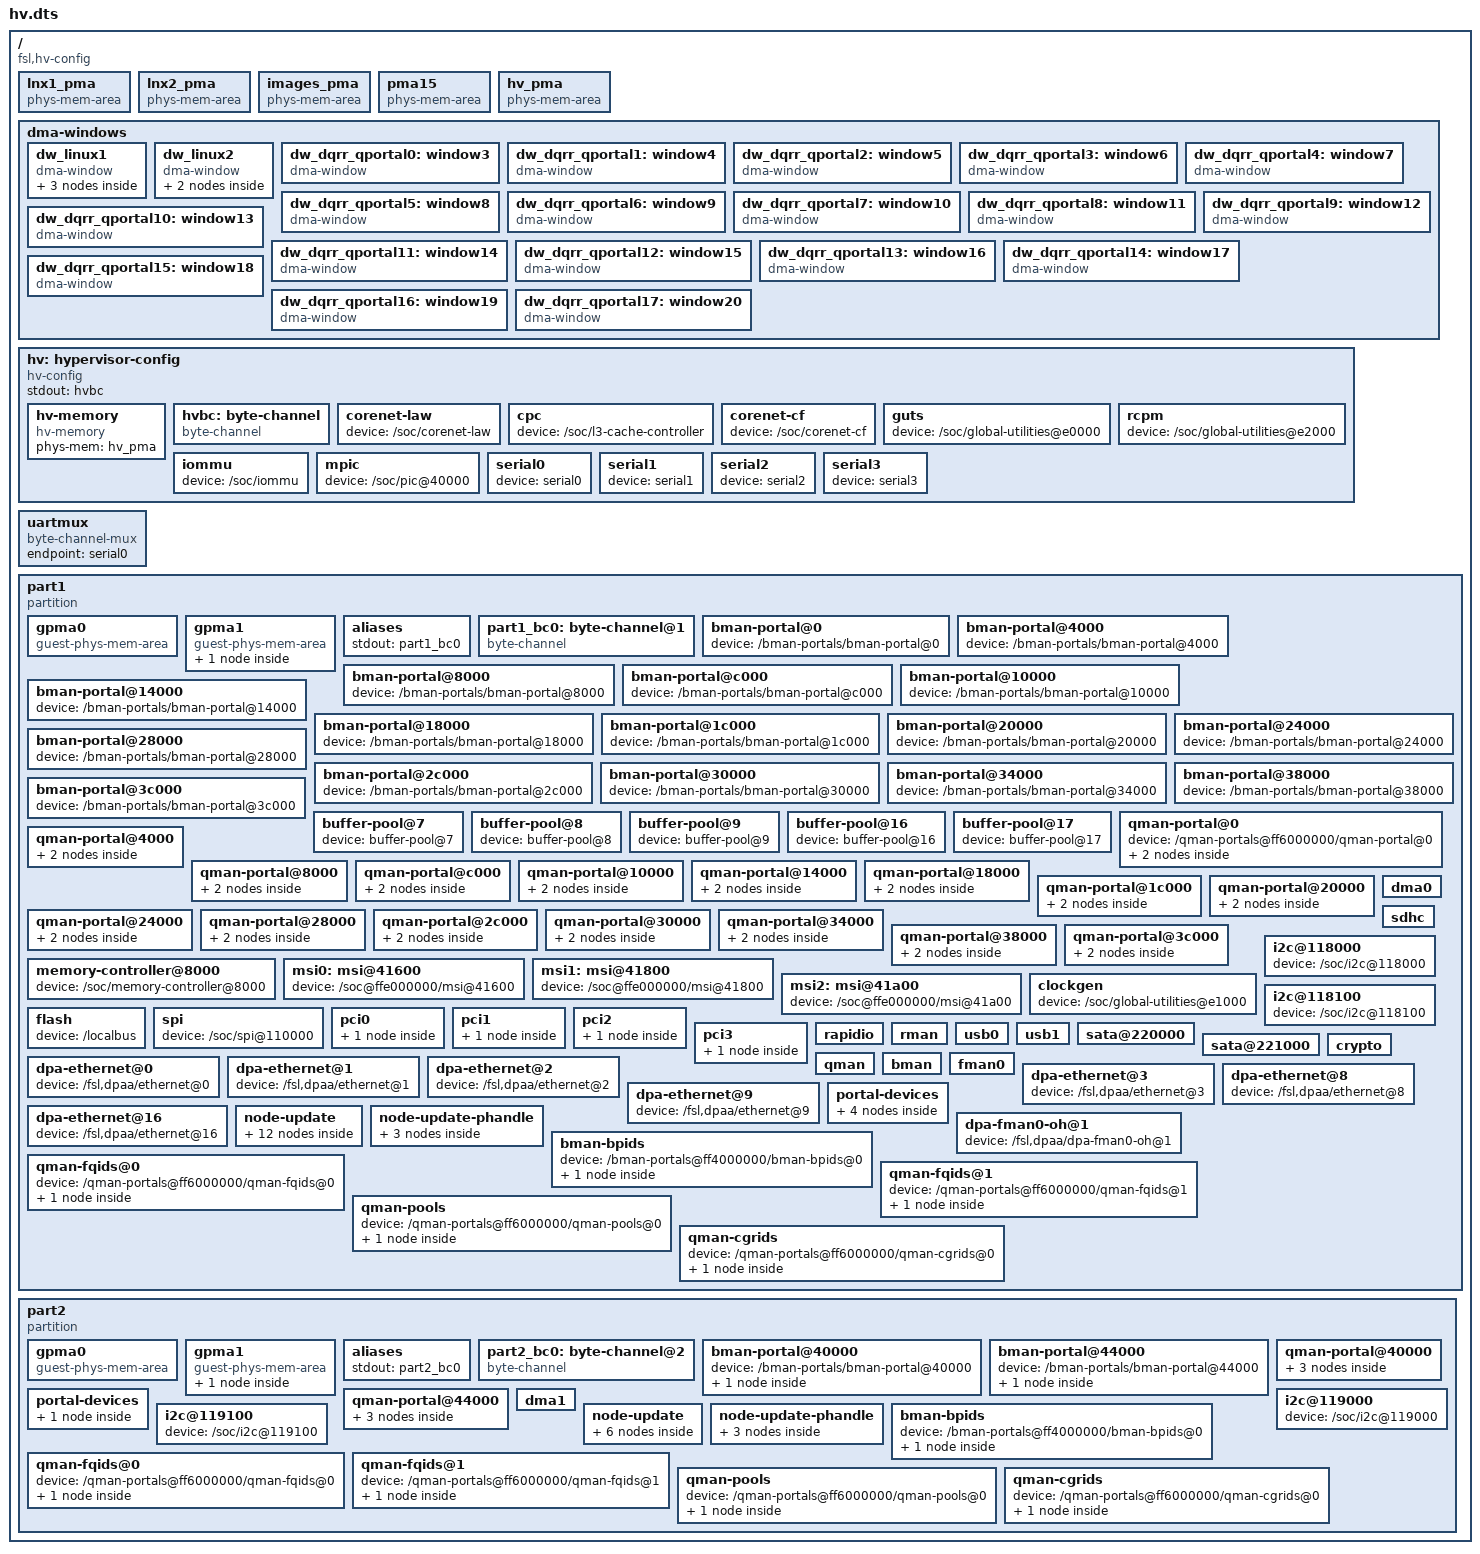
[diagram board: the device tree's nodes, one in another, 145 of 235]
/* Hypervisor Configuration tree containing all hypervisor configuration
 * parameters and partition definition information.
 * (Note -- Please refer to Hypervisor SW Reference Manual
 * (Chapter 5 Configuration) for further details)
 *
 * Copyright 2013 Freescale Semiconductor, Inc.
 */

/dts-v1/;

/ {	// root node

	// The root node of the configuration device tree must contain a
	// compatible property that identifies the device tree as a hypervisor

	compatible = "fsl,hv-config";

	// =====================================================
	// Physical Memory Areas
	// =====================================================
	lnx1_pma: lnx1_pma {
		compatible = "phys-mem-area";
		addr = <0x0 0x00000000>;	// Linux
		size = <0x0 0x40000000>;	// 1GB
	};

	lnx2_pma: lnx2_pma {
		compatible = "phys-mem-area";
		addr = <0x0 0x40000000>;	// Linux
		size = <0x0 0x20000000>;	// 512MB
	};

	images_pma: images_pma {
		compatible = "phys-mem-area";
		addr = <0x0 0x78000000>;	// Used for boot-from-RAM
		size = <0x0 0x04000000>;	// 64MB
	};

	pma15: pma15 {
		compatible = "phys-mem-area";
		addr = <0x0 0x7c000000>;	// For MAC-less Ethernet Linux1 and Linux2
		size = <0x0 0x01000000>;	// 16MB
	};

	hv_pma: hv_pma {
		compatible = "phys-mem-area";
		addr = <0x0 0x7f000000>;	// Hypervisor
		size = <0x0 0x01000000>;	// 16MB
	};

	// =====================================================
	// DMA Windows
	// =====================================================
	dma-windows {
		// DMA window for part1_linux
		dw_linux1: dw_linux1 {
			compatible = "dma-window";
			guest-addr = <0 0>;
			size = <0x1 0x00000000>; // 4GB
			subwindow-count = <4>;

			sub-window@0 {
				compatible = "dma-subwindow";
				guest-addr = <0 0>;
				size = <0 0x40000000>; // 1GB
			};

			// ====================================================
			// The window is used for MSIIR translation. The
			// hypervisor sets  a property in the guest device tree
			// (msi-address-64) which indicates the guest physical
			// address of the MSIIR register.
			// This address must be in the next page after the end
			// of DDR as seen by the guest. This is because, Linux
			// is extending the DDR ATMU with one page in order to
			// cover the MSIIR register.
			// ====================================================
			sub-window@1 {		// MSI sub-window
				compatible = "dma-subwindow";
				guest-addr = <0 0x40000000>;
				size = <0 0x1000>; // 4KB
				pcie-msi-subwindow;
			};

			sub-window@2 {		// Inter-partition region
				compatible = "dma-subwindow";
				guest-addr = <0 0x80000000>;
				size = <0 0x1000000>; // 16MB
			};
		};

		// DMA window for part2_linux
		dw_linux2: dw_linux2 {
			compatible = "dma-window";
			guest-addr = <0 0>;
			size = <0x1 0x00000000>; // 4GB
			subwindow-count = <4>;

			sub-window@0 {
				compatible = "dma-subwindow";
				guest-addr = <0 0>;
				size = <0 0x20000000>; // 512MB
			};

			sub-window@1 {		// Inter-partition region
				compatible = "dma-subwindow";
				guest-addr = <0 0x80000000>;
				size = <0 0x1000000>; // 16MB
			};
		};

		// DMA window for stash_dqrr for qman-portal0
		dw_dqrr_qportal0: window3 {
			compatible = "dma-window";
			guest-addr = <0xf 0xf6000000>;
			size = <0 0x4000>;
		};

		// DMA window for stash_dqrr for qman-portal1
		dw_dqrr_qportal1: window4 {
			compatible = "dma-window";
			guest-addr = <0xf 0xf6004000>;
			size = <0 0x4000>;
		};

		// DMA window for stash_dqrr for qman-portal2
		dw_dqrr_qportal2: window5 {
			compatible = "dma-window";
			guest-addr = <0xf 0xf6008000>;
			size = <0 0x4000>;
		};

		// DMA window for stash_dqrr for qman-portal3
		dw_dqrr_qportal3: window6 {
			compatible = "dma-window";
			guest-addr = <0xf 0xf600c000>;
			size = <0 0x4000>;
		};

		// DMA window for stash_dqrr for qman-portal4
		dw_dqrr_qportal4: window7 {
			compatible = "dma-window";
			guest-addr = <0xf 0xf6010000>;
			size = <0 0x4000>;
		};

		// DMA window for stash_dqrr for qman-portal5
		dw_dqrr_qportal5: window8 {
			compatible = "dma-window";
			guest-addr = <0xf 0xf6014000>;
			size = <0 0x4000>;
		};

		// DMA window for stash_dqrr for qman-portal6
		dw_dqrr_qportal6: window9 {
			compatible = "dma-window";
			guest-addr = <0xf 0xf6018000>;
			size = <0 0x4000>;
		};

		// DMA window for stash_dqrr for qman-portal7
		dw_dqrr_qportal7: window10 {
			compatible = "dma-window";
			guest-addr = <0xf 0xf601c000>;
			size = <0 0x4000>;
		};

		// DMA window for stash_dqrr for qman-portal8
		dw_dqrr_qportal8: window11 {
			compatible = "dma-window";
			guest-addr = <0xf 0xf6020000>;
			size = <0 0x4000>;
		};

		// DMA window for stash_dqrr for qman-portal9
		dw_dqrr_qportal9: window12 {
			compatible = "dma-window";
			guest-addr = <0xf 0xf6024000>;
			size = <0 0x4000>;
		};

		// DMA window for stash_dqrr for qman-portal10
		dw_dqrr_qportal10: window13 {
			compatible = "dma-window";
			guest-addr = <0xf 0xf6028000>;
			size = <0 0x4000>;
		};

		// DMA window for stash_dqrr for qman-portal11
		dw_dqrr_qportal11: window14 {
			compatible = "dma-window";
			guest-addr = <0xf 0xf602c000>;
			size = <0 0x4000>;
		};

		// DMA window for stash_dqrr for qman-portal12
		dw_dqrr_qportal12: window15 {
			compatible = "dma-window";
			guest-addr = <0xf 0xf6030000>;
			size = <0 0x4000>;
		};

		// DMA window for stash_dqrr for qman-portal13
		dw_dqrr_qportal13: window16 {
			compatible = "dma-window";
			guest-addr = <0xf 0xf6034000>;
			size = <0 0x4000>;
		};

		// DMA window for stash_dqrr for qman-portal14
		dw_dqrr_qportal14: window17 {
			compatible = "dma-window";
			guest-addr = <0xf 0xf6038000>;
			size = <0 0x4000>;
		};

		// DMA window for stash_dqrr for qman-portal15
		dw_dqrr_qportal15: window18 {
			compatible = "dma-window";
			guest-addr = <0xf 0xf603c000>;
			size = <0 0x4000>;
		};

		// DMA window for stash_dqrr for qman-portal16
		dw_dqrr_qportal16: window19 {
			compatible = "dma-window";
			guest-addr = <0xf 0xf6040000>;
			size = <0 0x4000>;
		};

		// DMA window for stash_dqrr for qman-portal17
		dw_dqrr_qportal17: window20 {
			compatible = "dma-window";
			guest-addr = <0xf 0xf6044000>;
			size = <0 0x4000>;
		};
	};

	// =====================================================
	// Hypervisor Config
	// Hypervisor is also configured via the Hypervisor
	// configuration tree. A special node and subtree defines
	// set of global configuration parameters and a number of
	// device nodes assigning I/O devices to the hypervisor
	// =====================================================
	hv: hypervisor-config {
		compatible = "hv-config";

		// phandle to byte-channel used for hypervisor's console
		stdout = <&hvbc>;

		hv-memory {
			compatible = "hv-memory";
			phys-mem = <&hv_pma>;
		};

		hvbc: byte-channel {
			compatible = "byte-channel";
			endpoint = <&uartmux>;
			mux-channel = <0>;
		};

		// Device nodes given below are the physical I/O
		// devices assigned to hypervisor
		corenet-law {
			device = "/soc/corenet-law";
		};

		cpc {
			device = "/soc/l3-cache-controller";
		};

		corenet-cf {
			device = "/soc/corenet-cf";
		};

		guts {
			device = "/soc/global-utilities@e0000";
		};

		rcpm {
			device = "/soc/global-utilities@e2000";
		};

		iommu {
			device = "/soc/iommu";
		};

		mpic {
			device = "/soc/pic@40000";
		};

		serial0: serial0 {
			device = "serial0";
		};

		serial1: serial1 {
			device = "serial1";
		};

		serial2: serial2 {
			device = "serial2";
		};

		serial3: serial3 {
			device = "serial3";
		};
	};

	// =====================================================
	// UART mux
	// This node is referenced by byte-channels that use mux
	// as an endpoint
	// =====================================================
	uartmux: uartmux {
		compatible = "byte-channel-mux";
		endpoint = <&serial0>;
	};

	// =====================================================
	// To keep the scenarios hv-1/2/4p as diff-able as possible
	// we always use labels part1, part2, part<n>
	// In hv-2p scenario, there are 2 partitions - 2 Linux
	// Partition1 --- part1 --- Linux partition
	// Partition2 --- part2 --- Linux partition
	// =====================================================

	// =====================================================
	// Partition 1
	// =====================================================
	part1 {
		// Indicates that it is a partition node
		compatible = "partition";
		label = "p1-linux";
		// CPUs #0 to #6 are assigned to this partition
		cpus = <0 7>;
		guest-image = <0xf 0xe8020000 0 0 0 0x700000>;
		linux-rootfs = <0xf 0xe9300000 0 0x01300000 0 0x02800000>;
		dtb-window = <0 0x1000000 0 0x20000>;

		// Temporary until Linux uses enable LIODN hcall
		no-dma-disable;
		direct-guest-tlb-miss;
		direct-guest-tlb-management;

		gpma0 {
			compatible = "guest-phys-mem-area";
			phys-mem = <&lnx1_pma>;
			guest-addr = <0 0>;
		};

		gpma1 {
			compatible = "guest-phys-mem-area";
			phys-mem = <&pma15>;	// Interpartition between Linux1 - Linux2
			guest-addr = <0 0x80000000>;
			node-update {
				delete-prop = "device_type";
			};
		};

		aliases {
			stdout = <&part1_bc0>;
		};

		// =====================================================
		// Devices assigned to the partition - device nodes
		// device node is child of partition node and is used to
		// assign physical I/O devices to partition
		// =====================================================
		part1_bc0: byte-channel@1 {
			compatible = "byte-channel";
			endpoint = <&uartmux>;
			mux-channel = <1>;
		};

		// Bman portals assigned to this partition
		bman-portal@0 {
			device = "/bman-portals/bman-portal@0";
		};

		bman-portal@4000 {
			device = "/bman-portals/bman-portal@4000";
		};

		bman-portal@8000 {
			device = "/bman-portals/bman-portal@8000";
		};

		bman-portal@c000 {
			device = "/bman-portals/bman-portal@c000";
		};

		bman-portal@10000 {
			device = "/bman-portals/bman-portal@10000";
		};

		bman-portal@14000 {
			device = "/bman-portals/bman-portal@14000";
		};

		bman-portal@18000 {
			device = "/bman-portals/bman-portal@18000";
		};

		bman-portal@1c000 {
			device = "/bman-portals/bman-portal@1c000";
		};

		bman-portal@20000 {
			device = "/bman-portals/bman-portal@20000";
		};

		bman-portal@24000 {
			device = "/bman-portals/bman-portal@24000";
		};

		bman-portal@28000 {
			device = "/bman-portals/bman-portal@28000";
		};

		bman-portal@2c000 {
			device = "/bman-portals/bman-portal@2c000";
		};

		bman-portal@30000 {
			device = "/bman-portals/bman-portal@30000";
		};

		bman-portal@34000 {
			device = "/bman-portals/bman-portal@34000";
		};

		bman-portal@38000 {
			device = "/bman-portals/bman-portal@38000";
		};

		bman-portal@3c000 {
			device = "/bman-portals/bman-portal@3c000";
		};

		// Bman buffer pools assigned to this partition
		buffer-pool@7 {
			device = "buffer-pool@7";
		};

		buffer-pool@8 {
			device = "buffer-pool@8";
		};

		buffer-pool@9 {
			device = "buffer-pool@9";
		};

		buffer-pool@16 {
			device = "buffer-pool@16";
		};

		buffer-pool@17 {
			device = "buffer-pool@17";
		};

		qman-portal@0 {
			device = "/qman-portals@ff6000000/qman-portal@0";

			stash-mem {
				liodn-index = <1>;
				dma-window = <&dw_linux1>;
				operation-mapping = <0>;
				stash-dest = <3>;
			};

			stash-dqrr {
				liodn-index = <0>;
				dma-window = <&dw_dqrr_qportal0>;
				operation-mapping = <0>;
				stash-dest = <3>;
			};
		};

		qman-portal@4000 {
			device = "/qman-portals@ff6000000/qman-portal@4000";

			stash-mem {
				liodn-index = <1>;
				dma-window = <&dw_linux1>;
				operation-mapping = <0>;
				stash-dest = <3>;
			};

			stash-dqrr {
				liodn-index = <0>;
				dma-window = <&dw_dqrr_qportal1>;
				operation-mapping = <0>;
				stash-dest = <3>;
			};
		};

		qman-portal@8000 {
			device = "/qman-portals@ff6000000/qman-portal@8000";

			stash-mem {
				liodn-index = <1>;
				dma-window = <&dw_linux1>;
				operation-mapping = <0>;
				stash-dest = <3>;
			};

			stash-dqrr {
				liodn-index = <0>;
				dma-window = <&dw_dqrr_qportal2>;
				operation-mapping = <0>;
				stash-dest = <3>;
			};
		};

		qman-portal@c000 {
			device = "/qman-portals@ff6000000/qman-portal@c000";

			stash-mem {
				liodn-index = <1>;
				dma-window = <&dw_linux1>;
				operation-mapping = <0>;
				stash-dest = <3>;
			};

			stash-dqrr {
				liodn-index = <0>;
				dma-window = <&dw_dqrr_qportal3>;
				operation-mapping = <0>;
				stash-dest = <3>;
			};
		};

		qman-portal@10000 {
			device = "/qman-portals@ff6000000/qman-portal@10000";

			stash-mem {
				liodn-index = <1>;
				dma-window = <&dw_linux1>;
				operation-mapping = <0>;
				stash-dest = <3>;
			};

			stash-dqrr {
				liodn-index = <0>;
				dma-window = <&dw_dqrr_qportal4>;
				operation-mapping = <0>;
				stash-dest = <3>;
			};
		};

		qman-portal@14000 {
			device = "/qman-portals@ff6000000/qman-portal@14000";

			stash-mem {
				liodn-index = <1>;
				dma-window = <&dw_linux1>;
				operation-mapping = <0>;
				stash-dest = <3>;
			};

			stash-dqrr {
				liodn-index = <0>;
				dma-window = <&dw_dqrr_qportal5>;
				operation-mapping = <0>;
				stash-dest = <3>;
			};
		};

		qman-portal@18000 {
			device = "/qman-portals@ff6000000/qman-portal@18000";

			stash-mem {
				liodn-index = <1>;
				dma-window = <&dw_linux1>;
				operation-mapping = <0>;
				stash-dest = <3>;
			};

			stash-dqrr {
				liodn-index = <0>;
				dma-window = <&dw_dqrr_qportal6>;
				operation-mapping = <0>;
				stash-dest = <3>;
			};
		};

		qman-portal@1c000 {
			device = "/qman-portals@ff6000000/qman-portal@1c000";

			stash-mem {
				liodn-index = <1>;
				dma-window = <&dw_linux1>;
				operation-mapping = <0>;
				stash-dest = <3>;
			};

			stash-dqrr {
				liodn-index = <0>;
				dma-window = <&dw_dqrr_qportal7>;
				operation-mapping = <0>;
				stash-dest = <3>;
			};
		};

		qman-portal@20000 {
			device = "/qman-portals@ff6000000/qman-portal@20000";

			stash-mem {
				liodn-index = <1>;
				dma-window = <&dw_linux1>;
				operation-mapping = <0>;
				stash-dest = <3>;
			};

			stash-dqrr {
				liodn-index = <0>;
				dma-window = <&dw_dqrr_qportal8>;
				operation-mapping = <0>;
				stash-dest = <3>;
			};
		};

		qman-portal@24000 {
			device = "/qman-portals@ff6000000/qman-portal@24000";

			stash-mem {
				liodn-index = <1>;
				dma-window = <&dw_linux1>;
				operation-mapping = <0>;
				stash-dest = <3>;
			};

			stash-dqrr {
				liodn-index = <0>;
				dma-window = <&dw_dqrr_qportal9>;
				operation-mapping = <0>;
				stash-dest = <3>;
			};
		};

		qman-portal@28000 {
			device = "/qman-portals@ff6000000/qman-portal@28000";

			stash-mem {
				liodn-index = <1>;
				dma-window = <&dw_linux1>;
				operation-mapping = <0>;
				stash-dest = <3>;
			};

			stash-dqrr {
				liodn-index = <0>;
				dma-window = <&dw_dqrr_qportal10>;
				operation-mapping = <0>;
				stash-dest = <3>;
			};
		};

		qman-portal@2c000 {
			device = "/qman-portals@ff6000000/qman-portal@2c000";

			stash-mem {
				liodn-index = <1>;
				dma-window = <&dw_linux1>;
				operation-mapping = <0>;
				stash-dest = <3>;
			};

			stash-dqrr {
				liodn-index = <0>;
				dma-window = <&dw_dqrr_qportal11>;
				operation-mapping = <0>;
				stash-dest = <3>;
			};
		};

		qman-portal@30000 {
			device = "/qman-portals@ff6000000/qman-portal@30000";

			stash-mem {
				liodn-index = <1>;
				dma-window = <&dw_linux1>;
				operation-mapping = <0>;
				stash-dest = <3>;
			};

			stash-dqrr {
				liodn-index = <0>;
				dma-window = <&dw_dqrr_qportal12>;
				operation-mapping = <0>;
				stash-dest = <3>;
			};
		};

		qman-portal@34000 {
			device = "/qman-portals@ff6000000/qman-portal@34000";

			stash-mem {
				liodn-index = <1>;
				dma-window = <&dw_linux1>;
				operation-mapping = <0>;
				stash-dest = <3>;
			};

			stash-dqrr {
				liodn-index = <0>;
				dma-window = <&dw_dqrr_qportal13>;
				operation-mapping = <0>;
				stash-dest = <3>;
			};
		};

		qman-portal@38000 {
			device = "/qman-portals@ff6000000/qman-portal@38000";

			stash-mem {
				liodn-index = <1>;
				dma-window = <&dw_linux1>;
				operation-mapping = <0>;
				stash-dest = <3>;
			};

			stash-dqrr {
				liodn-index = <0>;
				dma-window = <&dw_dqrr_qportal14>;
				operation-mapping = <0>;
				stash-dest = <3>;
			};
		};

		qman-portal@3c000 {
			device = "/qman-portals@ff6000000/qman-portal@3c000";

			stash-mem {
				liodn-index = <1>;
				dma-window = <&dw_linux1>;
				operation-mapping = <0>;
				stash-dest = <3>;
			};

			stash-dqrr {
				liodn-index = <0>;
				dma-window = <&dw_dqrr_qportal15>;
				operation-mapping = <0>;
				stash-dest = <3>;
			};
		};

		memory-controller@8000 {
			device = "/soc/memory-controller@8000";
		};

		msi0: msi@41600 {
			device = "/soc@ffe000000/msi@41600";
		};

		msi1: msi@41800 {
			device = "/soc@ffe000000/msi@41800";
		};

		msi2: msi@41a00 {
			device = "/soc@ffe000000/msi@41a00";
		};

		dma0 {
			device = "dma0";
			dma-window = <&dw_linux1>;
		};

		sdhc {
			device = "sdhc";
			dma-window = <&dw_linux1>;
		};

		clockgen {
			device = "/soc/global-utilities@e1000";
		};

		i2c@118000 {
			device = "/soc/i2c@118000";
		};

		i2c@118100 {
			device = "/soc/i2c@118100";
		};

		flash {
			device = "/localbus";
		};

		spi {
			device = "/soc/spi@110000";
		};

		pci0 {
			device = "pci0";
			map-ranges;
			dma-window = <&dw_linux1>;
			node-update-phandle {
				fsl,msi = <&msi0>;
			};
		};

		pci1 {
			device = "pci1";
			map-ranges;
			dma-window = <&dw_linux1>;
			node-update-phandle {
				fsl,msi = <&msi1>;
			};
		};

		pci2 {
			device = "pci2";
			map-ranges;
			dma-window = <&dw_linux1>;
			node-update-phandle {
				fsl,msi = <&msi2>;
			};
		};

		pci3 {
			device = "pci3";
			map-ranges;
			dma-window = <&dw_linux1>;
			node-update-phandle {
				fsl,msi = <&msi0>;
			};
		};

		rapidio {
			device = "rapidio@ffe0c0000";
			map-ranges;
			dma-window = <&dw_linux1>;
		};

		rman {
			device = "rman";
			dma-window = <&dw_linux1>;
		};

		usb0 {
			device = "/soc/usb@210000";
			dma-window = <&dw_linux1>;
		};

		usb1 {
			device = "usb1";
			dma-window = <&dw_linux1>;
		};

		sata@220000 {
			device = "/soc/sata@220000";
			dma-window = <&dw_linux1>;
		};

		sata@221000 {
			device = "/soc/sata@221000";
			dma-window = <&dw_linux1>;
		};

		crypto {
			device = "/soc/crypto";
			dma-window = <&dw_linux1>;
		};

		qman {
			device = "/soc/qman";
			dma-window = <&dw_linux1>;
			operation-mapping = <2>;	// OMI_QMAN_PRIV
			stash-dest = <3>;		// L3/CPC
		};

		bman {
			device = "/soc/bman";
			dma-window = <&dw_linux1>;
		};

		fman0 {
			device = "fman0";
			dma-window = <&dw_linux1>;
		};

		// FMAN0 XAUI - ethernet 0 assigned to this partition
		dpa-ethernet@0 {
			device = "/fsl,dpaa/ethernet@0";
		};

		// FMAN0 XAUI - ethernet 1 assigned to this partition
		dpa-ethernet@1 {
			device = "/fsl,dpaa/ethernet@1";
		};

		// FMAN0 RGMII -- ethernet 2 assigned to this partition
		dpa-ethernet@2 {
			device = "/fsl,dpaa/ethernet@2";
		};

		// FMAN0 RGMII -- ethernet 3 assigned to this partition
		dpa-ethernet@3 {
			device = "/fsl,dpaa/ethernet@3";
		};

		// FMAN0 XAUI - ethernet 8 assigned to this partition
		dpa-ethernet@8 {
			device = "/fsl,dpaa/ethernet@8";
		};

		// FMAN0 XAUI - ethernet 9 assigned to this partition
		dpa-ethernet@9 {
			device = "/fsl,dpaa/ethernet@9";
		};

		// MAC-less b/w kernel and USDPAA -- assigned to this partition
		dpa-ethernet@16 {
			device = "/fsl,dpaa/ethernet@16";
		};
		portal-devices {
			fman0 {
				device = "fman0";
				dma-window = <&dw_linux1>;
			};

			caam {
				device = "crypto";
				dma-window = <&dw_linux1>;
			};

			pme {
				device = "pme";
				dma-window = <&dw_linux1>;
			};

			rman {
				device = "rman";
				dma-window = <&dw_linux1>;
			};
		};

		node-update {
			#address-cells = <0x2>;
			#size-cells = <0x2>;
			reserved-memory {
				#address-cells = <0x2>;
				#size-cells = <0x2>;
				ranges;

				bman-fbpr {
					size = <0x0 0x1000000>;
					alignment = <0x0 0x1000000>;
					compatible = "fsl,bman-fbpr";
					alloc-ranges = <0x0 0x0 0x10000 0x0>;
					linux,phandle = <0x2a>;
					phandle = <0x2a>;
				};

				qman-fqd {
					size = <0x0 0x800000>;
					alignment = <0x0 0x800000>;
					compatible = "fsl,qman-fqd";
					alloc-ranges = <0x0 0x0 0x10000 0x0>;
					linux,phandle = <0x2c>;
					phandle = <0x2c>;
				};

				qman-pfdr {
					size = <0x0 0x2000000>;
					alignment = <0x0 0x2000000>;
					compatible = "fsl,qman-pfdr";
					alloc-ranges = <0x0 0x0 0x10000 0x0>;
					linux,phandle = <0x2d>;
					phandle = <0x2d>;
				};

				pme-pdsr {
					compatible = "fsl,pme-pdsr";
					alloc-ranges = <0x0 0x0 0x10000 0x0>;
					size = <0x0 0x1000000>;
					alignment = <0x0 0x1000000>;
					linux,phandle = <0x27>;
					phandle = <0x27>;
				};

				pme-sre {
					compatible = "fsl,pme-sre";
					alloc-ranges = <0x0 0x0 0x10000 0x0>;
					size = <0x0 0xa00000>;
					alignment = <0x0 0xa00000>;
					linux,phandle = <0x28>;
					phandle = <0x28>;
				};
			};

			// =====================================================
			// The buffer size value of 1728 (multiple of ODD cache
			// line) is calculated according to dpa_extra_headroom
			// which defaults to 64bytes.
			// If dpa_extra_headroom is set to 0 then the buffer
			// size will be 1600bytes (also multiple of odd cache
			// line). For any extra headroom values ranging between
			// 1 and 128bytes the buffer size is 1728bytes. For
			// values ranging between 129bytes and 256bytes, the
			// buffer size is 1856bytes and so on.
			// =====================================================
			part1_bp10: buffer-pool@10 {
				compatible = "fsl,t2080-bpool", "fsl,bpool";
				fsl,bpid = <10>;
				fsl,bpool-ethernet-cfg = <0 0x80 0 1728 0 0x80000000>;
				fsl,bpool-ethernet-seeds;
			};

			// =====================================================
			// Same comment as for part1_bp10
			// =====================================================
			part1_bp11: buffer-pool@11 {
				compatible = "fsl,t2080-bpool", "fsl,bpool";
				fsl,bpid = <11>;
				fsl,bpool-ethernet-cfg = <0 0x80 0 1728 0 0x80036000>;
				fsl,bpool-ethernet-seeds;
			};

			// Add a subnode dpa-ethernet@10 in fsl,dpaa node in GDT
			fsl,dpaa {
				compatible = "fsl,t2080-dpaa", "fsl,dpaa";

				// Link with Linux2 (MAC-less)
				dpa-ethernet@20 {
					compatible = "fsl,t2080-dpa-ethernet", "fsl,dpa-ethernet-macless";
					fsl,qman-frame-queues-rx = <0x4000 8>;
					fsl,qman-frame-queues-tx = <0x4008 8>;
					local-mac-address = [02 00 c0 a8 6f fe];
				};

				// Shared with Linux2 (Shared-MAC)
				// The interface has to be set to promiscuous mode!
				dpa-ethernet@0 {
					compatible = "fsl,t2080-dpa-ethernet", "fsl,dpa-ethernet-shared";
					fsl,qman-frame-queues-rx = <0x340 1 0x341 1 0x320 8>;
					fsl,qman-frame-queues-tx = <0x342 1 0x343 1 0x300 8>;
				};
			};

			chosen {
				bootargs = "bportals=0 qportals=0";
			};
		};

		node-update-phandle {
			fsl,dpaa {
				dpa-ethernet@20 {
					fsl,bman-buffer-pools = <&part1_bp10>;
				};

				dpa-ethernet@0 {
					fsl,bman-buffer-pools = <&part1_bp11>;
				};
			};
		};

		dpa-fman0-oh@1 {
			device = "/fsl,dpaa/dpa-fman0-oh@1";
		};

		bman-bpids {
			device = "/bman-portals@ff4000000/bman-bpids@0";

			node-update {
				fsl,bpid-range = <32 16>;
			};
		};

		qman-fqids@0 {
			device = "/qman-portals@ff6000000/qman-fqids@0";

			node-update {
				fsl,fqid-range = <0x100 0x100>;
			};
		};

		qman-fqids@1 {
			device = "/qman-portals@ff6000000/qman-fqids@1";

			node-update {
				fsl,fqid-range = <0x8000 0x4000>;
			};
		};

		qman-pools {
			device = "/qman-portals@ff6000000/qman-pools@0";

			node-update {
				fsl,pool-channel-range = <1033 7>;
			};
		};

		qman-cgrids {
			device = "/qman-portals@ff6000000/qman-cgrids@0";

			node-update {
				fsl,cgrid-range = <0x80 0x80>;
			};
		};
	};

	// =====================================================
	// Partition 2
	// =====================================================
	part2 {
		compatible = "partition";
		label = "p2-linux";
		// CPU #7 is assigned to this partition
		cpus = <7 1>;
		guest-image = <0xf 0xe8020000 0 0 0 0x700000>;
		linux-rootfs = <0xf 0xe9300000 0 0x01300000 0 0x02800000>;
		dtb-window = <0 0x1000000 0 0x20000>;

		// Temporary until Linux uses enable LIODN hcall
		no-dma-disable;
		direct-guest-tlb-miss;
		direct-guest-tlb-management;

		gpma0 {
			compatible = "guest-phys-mem-area";
			phys-mem = <&lnx2_pma>;
			guest-addr = <0 0>;
		};

		gpma1 {
			compatible = "guest-phys-mem-area";
			phys-mem = <&pma15>;	// Interpartition between Linux1 - Linux2
			guest-addr = <0 0x80000000>;
			node-update {
				delete-prop = "device_type";
			};
		};

		aliases {
			stdout = <&part2_bc0>;
		};

		// =====================================================
		// Devices assigned to the partition - device nodes
		// device node is child of partition node and is used to
		// assign physical I/O devices to partition
		// =====================================================
		part2_bc0: byte-channel@2 {
			compatible = "byte-channel";
			endpoint = <&uartmux>;
			mux-channel = <2>;
		};

		bman-portal@40000 {
			device = "/bman-portals/bman-portal@40000";
			node-update {
				delete-prop = "fsl,usdpaa-portal";
			};
		};

		bman-portal@44000 {
			device = "/bman-portals/bman-portal@44000";
			node-update {
				delete-prop = "fsl,usdpaa-portal";
			};
		};

		qman-portal@40000 {
			device = "/qman-portals@ff6000000/qman-portal@40000";

			node-update {
				delete-prop = "fsl,usdpaa-portal";
				delete-node = "pme@0", "crypto@0", "rman@0";
			};

			stash-mem {
				liodn-index = <1>;
				dma-window = <&dw_linux2>;
				operation-mapping = <0>;
				stash-dest = <3>;
			};

			stash-dqrr {
				liodn-index = <0>;
				dma-window = <&dw_dqrr_qportal16>;
				operation-mapping = <0>;
				stash-dest = <3>;
			};
		};

		qman-portal@44000 {
			device = "/qman-portals@ff6000000/qman-portal@44000";

			node-update {
				delete-prop = "fsl,usdpaa-portal";
				delete-node = "pme@0", "crypto@0", "rman@0";
			};

			stash-mem {
				liodn-index = <1>;
				dma-window = <&dw_linux2>;
				operation-mapping = <0>;
				stash-dest = <3>;
			};

			stash-dqrr {
				liodn-index = <0>;
				dma-window = <&dw_dqrr_qportal17>;
				operation-mapping = <0>;
				stash-dest = <3>;
			};
		};

		// =====================================================
		// In Shared-MAC scenario, PAMU is using Fman's LIODN in
		// order to authorize tranzactions for the second
		// partition, thus the fman node have to be included in
		// the second partition, so that PAMU to be configured
		// accordingly.
		// =====================================================
		portal-devices {
			fman0 {
				device = "fman0";
				dma-window = <&dw_linux2>;
			};
		};

		dma1 {
			device = "dma1";
			dma-window = <&dw_linux2>;
		};

		i2c@119000 {
			device = "/soc/i2c@119000";
		};

		i2c@119100 {
			device = "/soc/i2c@119100";
		};

		node-update {
			// =====================================================
			// Even though it's part1 that seeds these buffer pools,
			// their "fsl,bpool-ethernet-cfg" properties must match
			// those in part1 exactly, since the resulting buffer
			// addresses will be exchanged between the partitions
			// through QMan, via FDs, without further translation.
			// Furthermore, the addresses must be mapable in both
			// guests, and, when mapped on either guest,
			// each should point to the same physical memory,
			// otherwise a segfault/machine check will occur.
			//
			// Same comment as for part1_bp10
			// =====================================================
			part2_bp10: buffer-pool@10 {
				compatible = "fsl,t2080-bpool", "fsl,bpool";
				fsl,bpid = <10>;
				fsl,bpool-ethernet-cfg = <0 0x80 0 1728 0 0x80000000>;
			};

			// =====================================================
			// Same comment as for part1_bp10
			// =====================================================
			part2_bp11: buffer-pool@11 {
				compatible = "fsl,t2080-bpool", "fsl,bpool";
				fsl,bpid = <11>;
				fsl,bpool-ethernet-cfg = <0 0x80 0 1728 0 0x80036000>;
			};

			fsl,dpaa {
				compatible = "fsl,t2080-dpaa", "fsl,dpaa";

				// =====================================================
				// Link with Linux1 (MAC-less)
				// The TX/RX queues of this interface are same with the
				// RX/TX queues of the interface dpa-ethernet@10 in
				// partition 1
				// =====================================================
				dpa-ethernet@10 {
					compatible = "fsl,t2080-dpa-ethernet", "fsl,dpa-ethernet-macless";
					fsl,qman-frame-queues-rx = <0x4008 8>;
					fsl,qman-frame-queues-tx = <0x4000 8>;
					local-mac-address = [02 00 c0 a8 79 fe];
				};

				// =====================================================
				// Shared with Linux1 (Shared-MAC)
				// The TX queues of this interface are the same with the
				// TX queues of the interface dpa-ethernet@0 in
				// partition 1; the RX queues are different
				// =====================================================
				dpa-ethernet@20 {
					compatible = "fsl,t2080-dpa-ethernet", "fsl,dpa-ethernet-macless";
					fsl,qman-frame-queues-rx = <0x350 8>;
					fsl,qman-frame-queues-tx = <0x300 8>;
					delete-prop = "fsl,fman-mac";
					local-mac-address = [02 00 c0 a8 a1 fe];
				};
			};

			chosen {
				bootargs = "bportals=0 qportals=0";
			};
		};

		node-update-phandle {
			fsl,dpaa {
				dpa-ethernet@10 {
					fsl,bman-buffer-pools = <&part2_bp10>;
				};

				dpa-ethernet@20 {
					fsl,bman-buffer-pools = <&part2_bp11>;
				};
			};
		};

		bman-bpids {
			device = "/bman-portals@ff4000000/bman-bpids@0";

			node-update {
				fsl,bpid-range = <48 16>;
			};
		};

		qman-fqids@0 {
			device = "/qman-portals@ff6000000/qman-fqids@0";

			node-update {
				fsl,fqid-range = <0x200 0x100>;
			};
		};

		qman-fqids@1 {
			device = "/qman-portals@ff6000000/qman-fqids@1";

			node-update {
				fsl,fqid-range = <0xC000 0x4000>;
			};
		};

		qman-pools {
			device = "/qman-portals@ff6000000/qman-pools@0";

			node-update {
				fsl,pool-channel-range = <1025 8>;
			};
		};

		qman-cgrids {
			device = "/qman-portals@ff6000000/qman-cgrids@0";

			node-update {
				fsl,cgrid-range = <0 0x80>;
			};
		};
	};
};
